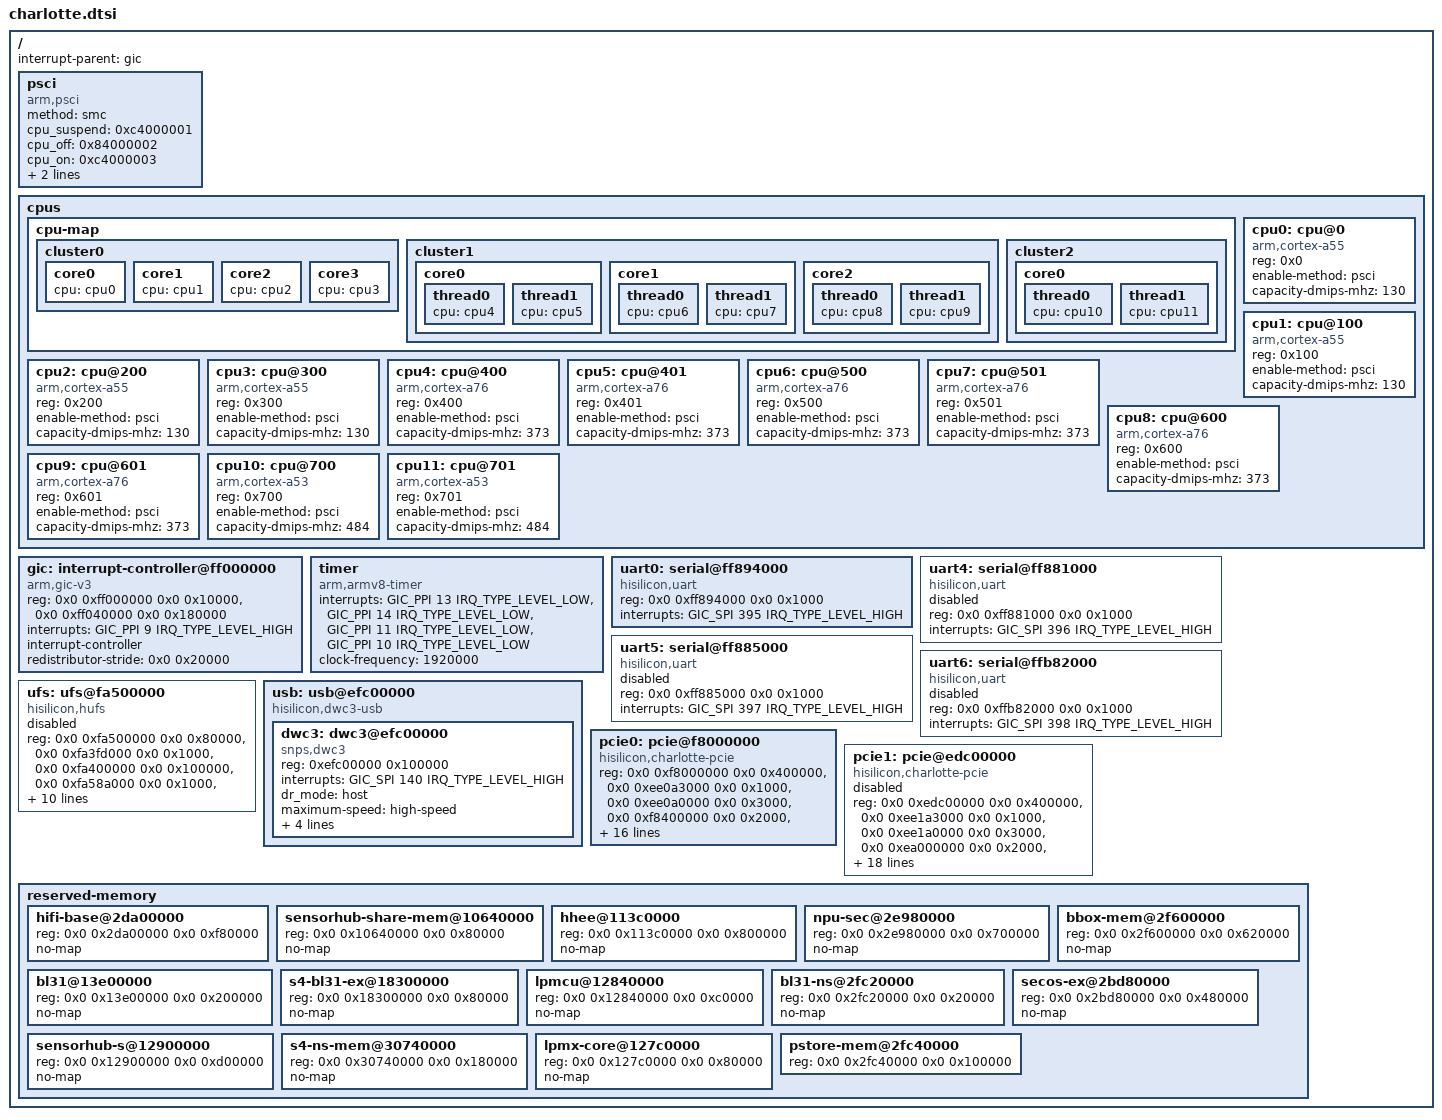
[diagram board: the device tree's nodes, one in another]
// SPDX-License-Identifier: GPL-2.0-only
/*
 * Minimal HiSilicon Kirin 9000C ("charlotte") SoC description.
 *
 * Derived from the live vendor device tree:
 *   dtc -I fs -O dts -o hisi-charlotte-current.dts /proc/device-tree
 *
 * This is a bring-up skeleton, not a complete board description.
 * The vendor UART, UFS, PMIC, DPU, GPU, and secure-world drivers are not
 * present in mainline.  Only the architectural pieces needed for early
 * boot are described here.
 */

#include <dt-bindings/interrupt-controller/arm-gic.h>
#include <dt-bindings/interrupt-controller/irq.h>

/ {
	#address-cells = <2>;
	#size-cells = <2>;
	interrupt-parent = <&gic>;

	psci {
		compatible = "arm,psci";
		method = "smc";
		cpu_suspend = <0xc4000001>;
		cpu_off = <0x84000002>;
		cpu_on = <0xc4000003>;
		system_reset = <0x84000009>;
		system_off = <0x84000008>;
	};

	cpus {
		#address-cells = <1>;
		#size-cells = <0>;

		cpu-map {
			cluster0 {
				core0 { cpu = <&cpu0>; };
				core1 { cpu = <&cpu1>; };
				core2 { cpu = <&cpu2>; };
				core3 { cpu = <&cpu3>; };
			};

			cluster1 {
				core0 {
					thread0 { cpu = <&cpu4>; };
					thread1 { cpu = <&cpu5>; };
				};
				core1 {
					thread0 { cpu = <&cpu6>; };
					thread1 { cpu = <&cpu7>; };
				};
				core2 {
					thread0 { cpu = <&cpu8>; };
					thread1 { cpu = <&cpu9>; };
				};
			};

			cluster2 {
				core0 {
					thread0 { cpu = <&cpu10>; };
					thread1 { cpu = <&cpu11>; };
				};
			};
		};

		cpu0: cpu@0 {
			device_type = "cpu";
			compatible = "arm,cortex-a55";
			reg = <0x0>;
			enable-method = "psci";
			capacity-dmips-mhz = <130>;
		};

		cpu1: cpu@100 {
			device_type = "cpu";
			compatible = "arm,cortex-a55";
			reg = <0x100>;
			enable-method = "psci";
			capacity-dmips-mhz = <130>;
		};

		cpu2: cpu@200 {
			device_type = "cpu";
			compatible = "arm,cortex-a55";
			reg = <0x200>;
			enable-method = "psci";
			capacity-dmips-mhz = <130>;
		};

		cpu3: cpu@300 {
			device_type = "cpu";
			compatible = "arm,cortex-a55";
			reg = <0x300>;
			enable-method = "psci";
			capacity-dmips-mhz = <130>;
		};

		cpu4: cpu@400 {
			device_type = "cpu";
			compatible = "arm,cortex-a76";
			reg = <0x400>;
			enable-method = "psci";
			capacity-dmips-mhz = <373>;
		};

		cpu5: cpu@401 {
			device_type = "cpu";
			compatible = "arm,cortex-a76";
			reg = <0x401>;
			enable-method = "psci";
			capacity-dmips-mhz = <373>;
		};

		cpu6: cpu@500 {
			device_type = "cpu";
			compatible = "arm,cortex-a76";
			reg = <0x500>;
			enable-method = "psci";
			capacity-dmips-mhz = <373>;
		};

		cpu7: cpu@501 {
			device_type = "cpu";
			compatible = "arm,cortex-a76";
			reg = <0x501>;
			enable-method = "psci";
			capacity-dmips-mhz = <373>;
		};

		cpu8: cpu@600 {
			device_type = "cpu";
			compatible = "arm,cortex-a76";
			reg = <0x600>;
			enable-method = "psci";
			capacity-dmips-mhz = <373>;
		};

		cpu9: cpu@601 {
			device_type = "cpu";
			compatible = "arm,cortex-a76";
			reg = <0x601>;
			enable-method = "psci";
			capacity-dmips-mhz = <373>;
		};

		cpu10: cpu@700 {
			device_type = "cpu";
			compatible = "arm,cortex-a53";
			reg = <0x700>;
			enable-method = "psci";
			capacity-dmips-mhz = <484>;
		};

		cpu11: cpu@701 {
			device_type = "cpu";
			compatible = "arm,cortex-a53";
			reg = <0x701>;
			enable-method = "psci";
			capacity-dmips-mhz = <484>;
		};
	};

	gic: interrupt-controller@ff000000 {
		compatible = "arm,gic-v3";
		reg = <0x0 0xff000000 0x0 0x10000>,
		      <0x0 0xff040000 0x0 0x180000>;
		interrupts = <GIC_PPI 9 IRQ_TYPE_LEVEL_HIGH>;
		interrupt-controller;
		#interrupt-cells = <3>;
		redistributor-stride = <0x0 0x20000>;
	};

	timer {
		compatible = "arm,armv8-timer";
		interrupts = <GIC_PPI 13 IRQ_TYPE_LEVEL_LOW>,
			     <GIC_PPI 14 IRQ_TYPE_LEVEL_LOW>,
			     <GIC_PPI 11 IRQ_TYPE_LEVEL_LOW>,
			     <GIC_PPI 10 IRQ_TYPE_LEVEL_LOW>;
		clock-frequency = <1920000>;
	};

	/*
	 * UART V500.  The vendor driver is not in mainline.  The node is kept
	 * here so a ported earlycon driver can match it and so the board DTS
	 * can point chosen/stdout-path at the real console UART.
	 */
	uart0: serial@ff894000 {
		compatible = "hisilicon,uart";
		reg = <0x0 0xff894000 0x0 0x1000>;
		interrupts = <GIC_SPI 395 IRQ_TYPE_LEVEL_HIGH>;
		status = "okay";
	};

	uart4: serial@ff881000 {
		compatible = "hisilicon,uart";
		reg = <0x0 0xff881000 0x0 0x1000>;
		interrupts = <GIC_SPI 396 IRQ_TYPE_LEVEL_HIGH>;
		status = "disabled";
	};

	uart5: serial@ff885000 {
		compatible = "hisilicon,uart";
		reg = <0x0 0xff885000 0x0 0x1000>;
		interrupts = <GIC_SPI 397 IRQ_TYPE_LEVEL_HIGH>;
		status = "disabled";
	};

	uart6: serial@ffb82000 {
		compatible = "hisilicon,uart";
		reg = <0x0 0xffb82000 0x0 0x1000>;
		interrupts = <GIC_SPI 398 IRQ_TYPE_LEVEL_HIGH>;
		status = "disabled";
	};

	/*
	 * Huawei UFS host controller ("hufs"), not the older
	 * hisilicon,hi3660-ufs/hi3670-ufs block handled by mainline
	 * drivers/ufs/host/ufs-hisi.c.
	 *
	 * Keep disabled until the vendor hufs_hcd/hufs_plat/hufs_mphy
	 * stack is ported.  The mainline ufs-hisi driver must not bind
	 * to this compatible.
	 */
	ufs: ufs@fa500000 {
		compatible = "hisilicon,hufs";
		reg = <0x0 0xfa500000 0x0 0x80000>,
		      <0x0 0xfa3fd000 0x0 0x1000>,
		      <0x0 0xfa400000 0x0 0x100000>,
		      <0x0 0xfa58a000 0x0 0x1000>,
		      <0x0 0xfb8c3000 0x0 0x1000>;
		interrupts = <GIC_SPI 134 IRQ_TYPE_LEVEL_HIGH>,
			     <GIC_SPI 120 IRQ_TYPE_LEVEL_HIGH>,
			     <GIC_SPI 121 IRQ_TYPE_LEVEL_HIGH>,
			     <GIC_SPI 122 IRQ_TYPE_LEVEL_HIGH>,
			     <GIC_SPI 123 IRQ_TYPE_LEVEL_HIGH>,
			     <GIC_SPI 124 IRQ_TYPE_LEVEL_HIGH>,
			     <GIC_SPI 125 IRQ_TYPE_LEVEL_HIGH>,
			     <GIC_SPI 126 IRQ_TYPE_LEVEL_HIGH>,
			     <GIC_SPI 127 IRQ_TYPE_LEVEL_HIGH>;
		status = "disabled";
	};

	/*
	 * USB2 host path for bring-up/CLI input.  The vendor glue driver
	 * "hisilicon,dwc3-usb" is handled by the mainline dwc3-of-simple
	 * glue, which only enables optional clocks/resets and populates the
	 * snps,dwc3 child.
	 *
	 * No PHY node is attached yet.  USB2 PHY/VBUS are expected to be
	 * left configured by UEFI; if that is not true, the vendor
	 * usb2-phy-t5/combophy port is the next step.
	 */
	usb: usb@efc00000 {
		compatible = "hisilicon,dwc3-usb";
		#address-cells = <1>;
		#size-cells = <1>;
		ranges;
		status = "okay";

		dwc3: dwc3@efc00000 {
			compatible = "snps,dwc3";
			reg = <0xefc00000 0x100000>;
			interrupts = <GIC_SPI 140 IRQ_TYPE_LEVEL_HIGH>;
			dr_mode = "host";
			maximum-speed = "high-speed";
			phy_type = "utmi";
			snps,hsphy_interface = "utmi";
			snps,dis_u2_susphy_quirk;
			snps,dis_u3_susphy_quirk;
			status = "okay";
		};
	};

	/*
	 * PCIe0: onboard ASMedia ASM1064 SATA controller (x1, Gen3).
	 * PCIe1: external x1 slot (currently empty).
	 * Both root complexes are Huawei kport blocks around a DW core.
	 */
	pcie0: pcie@f8000000 {
		compatible = "hisilicon,charlotte-pcie";
		device_type = "pci";
		reg = <0x0 0xf8000000 0x0 0x400000>,
		      <0x0 0xee0a3000 0x0 0x1000>,
		      <0x0 0xee0a0000 0x0 0x3000>,
		      <0x0 0xf8400000 0x0 0x2000>,
		      <0x0 0xee262000 0x0 0x1000>,
		      <0x0 0xee263000 0x0 0x1000>,
		      <0x0 0xfb21b000 0x0 0x1000>,
		      <0x0 0xffb81000 0x0 0x1000>,
		      <0x0 0xff806000 0x0 0x1000>;
		reg-names = "dbi", "apb", "phy", "config",
			    "crg", "pll", "sctrl", "pmctrl", "gpio";
		perst-gpio = <14>;
		#address-cells = <3>;
		#size-cells = <2>;
		#interrupt-cells = <1>;
		interrupt-map-mask = <0 0 0 7>;
		interrupt-map = <0 0 0 1 &gic GIC_SPI 93 IRQ_TYPE_LEVEL_HIGH>,
				<0 0 0 2 &gic GIC_SPI 94 IRQ_TYPE_LEVEL_HIGH>,
				<0 0 0 3 &gic GIC_SPI 95 IRQ_TYPE_LEVEL_HIGH>,
				<0 0 0 4 &gic GIC_SPI 96 IRQ_TYPE_LEVEL_HIGH>;
		bus-range = <0 0xff>;
		ranges = <0x02000000 0x0 0xf8500000 0x0 0xf8500000 0x0 0x01d00000>;
		num-lanes = <1>;
		max-link-speed = <3>;
		rc-id = <0>;
		status = "okay";
	};


	/* PCIe1: external x1 slot (ASM1064 sits on PCIe0). */
	pcie1: pcie@edc00000 {
		compatible = "hisilicon,charlotte-pcie";
		device_type = "pci";
		reg = <0x0 0xedc00000 0x0 0x400000>,
		      <0x0 0xee1a3000 0x0 0x1000>,
		      <0x0 0xee1a0000 0x0 0x3000>,
		      <0x0 0xea000000 0x0 0x2000>,
		      <0x0 0xee262000 0x0 0x1000>,
		      <0x0 0xee263000 0x0 0x1000>,
		      <0x0 0xfb21b000 0x0 0x1000>,
		      <0x0 0xffb81000 0x0 0x1000>,
		      <0x0 0xee267000 0x0 0x1000>;
		reg-names = "dbi", "apb", "phy", "config",
			    "crg", "pll", "sctrl", "pmctrl", "gpio";
		perst-gpio = <9>;
		#address-cells = <3>;
		#size-cells = <2>;
		#interrupt-cells = <1>;
		interrupt-map-mask = <0 0 0 7>;
		interrupt-map = <0 0 0 1 &gic GIC_SPI 104 IRQ_TYPE_LEVEL_HIGH>,
				<0 0 0 2 &gic GIC_SPI 105 IRQ_TYPE_LEVEL_HIGH>,
				<0 0 0 3 &gic GIC_SPI 106 IRQ_TYPE_LEVEL_HIGH>,
				<0 0 0 4 &gic GIC_SPI 107 IRQ_TYPE_LEVEL_HIGH>;
		bus-range = <0 0xff>;
		ranges = <0x02000000 0x0 0xea100000 0x0 0xea100000 0x0 0x03b00000>;
		num-lanes = <1>;
		max-link-speed = <3>;
		rc-id = <1>;
		/* DBI of this RC is not accessible yet on a cold boot;
		 * keep it disabled until a card is present and its power
		 * sequencing can be debugged against the vendor driver.
		 */
		status = "disabled";
	};
	reserved-memory {
		#address-cells = <2>;
		#size-cells = <2>;
		ranges;

		hifi-base@2da00000 {
			reg = <0x0 0x2da00000 0x0 0xf80000>;
			no-map;
		};

		sensorhub-share-mem@10640000 {
			reg = <0x0 0x10640000 0x0 0x80000>;
			no-map;
		};

		hhee@113c0000 {
			reg = <0x0 0x113c0000 0x0 0x800000>;
			no-map;
		};

		npu-sec@2e980000 {
			reg = <0x0 0x2e980000 0x0 0x700000>;
			no-map;
		};

		bbox-mem@2f600000 {
			reg = <0x0 0x2f600000 0x0 0x620000>;
			no-map;
		};

		bl31@13e00000 {
			reg = <0x0 0x13e00000 0x0 0x200000>;
			no-map;
		};

		s4-bl31-ex@18300000 {
			reg = <0x0 0x18300000 0x0 0x80000>;
			no-map;
		};

		lpmcu@12840000 {
			reg = <0x0 0x12840000 0x0 0xc0000>;
			no-map;
		};

		bl31-ns@2fc20000 {
			reg = <0x0 0x2fc20000 0x0 0x20000>;
			no-map;
		};

		secos-ex@2bd80000 {
			reg = <0x0 0x2bd80000 0x0 0x480000>;
			no-map;
		};

		sensorhub-s@12900000 {
			reg = <0x0 0x12900000 0x0 0xd00000>;
			no-map;
		};

		s4-ns-mem@30740000 {
			reg = <0x0 0x30740000 0x0 0x180000>;
			no-map;
		};

		lpmx-core@127c0000 {
			reg = <0x0 0x127c0000 0x0 0x80000>;
			no-map;
		};

		pstore-mem@2fc40000 {
			reg = <0x0 0x2fc40000 0x0 0x100000>;
		};
	};
};
